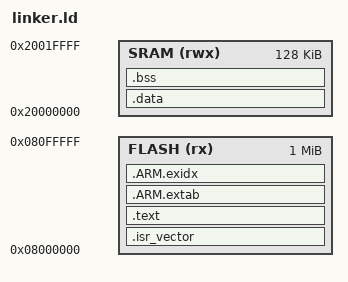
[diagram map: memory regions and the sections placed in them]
/* STM32F407VG Linker Script */
MEMORY
{
    FLASH (rx)  : ORIGIN = 0x08000000, LENGTH = 1024K
    SRAM (rwx)  : ORIGIN = 0x20000000, LENGTH = 128K
}

_estack = ORIGIN(SRAM) + LENGTH(SRAM);

SECTIONS
{
    .isr_vector :
    {
        . = ALIGN(4);
        KEEP(*(.isr_vector))
        . = ALIGN(4);
    } >FLASH

    .text :
    {
        . = ALIGN(4);
        *(.text)
        *(.text*)
        *(.rodata)
        *(.rodata*)
        . = ALIGN(4);
    } >FLASH

    .ARM.extab :
    {
        *(.ARM.extab*)
    } >FLASH

    .ARM.exidx :
    {
        *(.ARM.exidx*)
    } >FLASH

    _etext = .;

    .data : AT(_etext)
    {
        . = ALIGN(4);
        _sdata = .;
        *(.data)
        *(.data*)
        . = ALIGN(4);
        _edata = .;
    } >SRAM

    .bss :
    {
        . = ALIGN(4);
        _sbss = .;
        *(.bss)
        *(.bss*)
        *(COMMON)
        . = ALIGN(4);
        _ebss = .;
    } >SRAM
}
